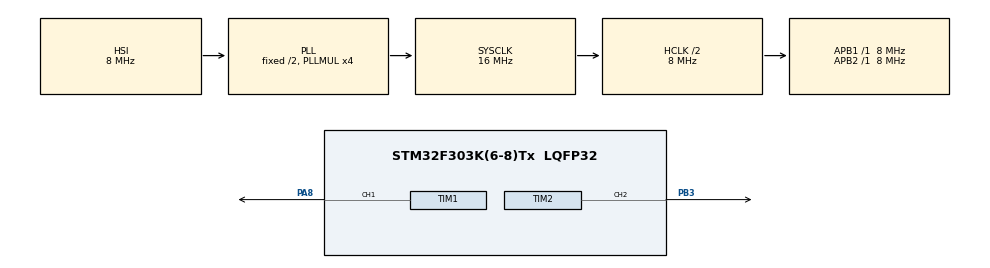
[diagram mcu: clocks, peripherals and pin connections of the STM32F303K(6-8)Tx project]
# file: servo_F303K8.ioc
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Mcu.Family=STM32F3
Mcu.Name=STM32F303K(6-8)Tx
Mcu.Package=LQFP32
NVIC.PriorityGroup=NVIC_PRIORITYGROUP_4
PA8.Signal=S_TIM1_CH1
PB3.Signal=S_TIM2_CH2
ProjectManager.HeapSize=0x200
ProjectManager.StackSize=0x400
ProjectManager.TargetToolchain=STM32CubeIDE
RCC.AHBCLKDivider=RCC_SYSCLK_DIV2
RCC.AHBFreq_Value=8000000
RCC.APB1Freq_Value=8000000
RCC.APB1TimFreq_Value=8000000
RCC.APB2Freq_Value=8000000
RCC.APB2TimFreq_Value=8000000
RCC.CortexFreq_Value=8000000
RCC.HCLKFreq_Value=8000000
RCC.HSE_VALUE=8000000
RCC.HSI_VALUE=8000000
RCC.PLLMUL=RCC_PLL_MUL4
RCC.SYSCLKFreq_VALUE=16000000
RCC.SYSCLKSourceVirtual=RCC_SYSCLKSOURCE_PLLCLK
SH.S_TIM1_CH1.0=TIM1_CH1,PWM Generation1 CH1
SH.S_TIM2_CH2.0=TIM2_CH2,PWM Generation2 CH2
TIM1.Channel-PWM\ Generation1\ CH1=TIM_CHANNEL_1
TIM1.Period=255
TIM1.Prescaler=624
TIM2.Channel-PWM\ Generation2\ CH2=TIM_CHANNEL_2
TIM2.Period=255
TIM2.Prescaler=625
VP_TIM1_VS_ClockSourceINT.Mode=Internal
VP_TIM2_VS_ClockSourceINT.Mode=Internal
board=custom

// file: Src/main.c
/* USER CODE BEGIN Header */
/**
  ******************************************************************************
  * @file           : main.c
  * @brief          : Main program body
  ******************************************************************************
  * @attention
  *
  * <h2><center>&copy; Copyright (c) 2020 STMicroelectronics.
  * All rights reserved.</center></h2>
  *
  * This software component is licensed by ST under BSD 3-Clause license,
  * the "License"; You may not use this file except in compliance with the
  * License. You may obtain a copy of the License at:
  *                        opensource.org/licenses/BSD-3-Clause
  *
  ******************************************************************************
  */
/* USER CODE END Header */

#include "main.h"

TIM_HandleTypeDef htim1;
TIM_HandleTypeDef htim2;

void SystemClock_Config(void);
static void MX_GPIO_Init(void);
static void MX_TIM1_Init(void);
static void MX_TIM2_Init(void);

int main(void)
{

  /* MCU Configuration--------------------------------------------------------*/

  /* Reset of all peripherals, Initializes the Flash interface and the Systick. */
  HAL_Init();

  /* Configure the system clock */
  SystemClock_Config();

  /* Initialize all configured peripherals */
  MX_GPIO_Init();
  MX_TIM1_Init();
  MX_TIM2_Init();
  /* USER CODE BEGIN 2 */
  char txbuf[30]={0};
   uint16_t value=0;
   short duty;

   HAL_TIM_PWM_Start(&htim1,TIM_CHANNEL_1);
   HAL_TIM_PWM_Start(&htim2,TIM_CHANNEL_2);

  /* USER CODE END 2 */

  /* Infinite loop */
  while (1)
  {

    /* USER CODE BEGIN 3 */

	  duty=8;
	 __HAL_TIM_SET_COMPARE(&htim1,TIM_CHANNEL_1,duty);
	 __HAL_TIM_SET_COMPARE(&htim2,TIM_CHANNEL_2,0);
	 HAL_Delay(1000);
     duty=32;
      __HAL_TIM_SET_COMPARE(&htim1,TIM_CHANNEL_1,duty);
      __HAL_TIM_SET_COMPARE(&htim2,TIM_CHANNEL_2,50);
      HAL_Delay(1000);

  }
  /* USER CODE END 3 */
}

void SystemClock_Config(void)
{
  RCC_OscInitTypeDef RCC_OscInitStruct = {0};
  RCC_ClkInitTypeDef RCC_ClkInitStruct = {0};
  RCC_PeriphCLKInitTypeDef PeriphClkInit = {0};

  /** Initializes the CPU, AHB and APB busses clocks
  */
  RCC_OscInitStruct.OscillatorType = RCC_OSCILLATORTYPE_HSI;
  RCC_OscInitStruct.HSIState = RCC_HSI_ON;
  RCC_OscInitStruct.HSICalibrationValue = RCC_HSICALIBRATION_DEFAULT;
  RCC_OscInitStruct.PLL.PLLState = RCC_PLL_ON;
  RCC_OscInitStruct.PLL.PLLSource = RCC_PLLSOURCE_HSI;
  RCC_OscInitStruct.PLL.PLLMUL = RCC_PLL_MUL4;
  if (HAL_RCC_OscConfig(&RCC_OscInitStruct) != HAL_OK)
  {
    Error_Handler();
  }
  /** Initializes the CPU, AHB and APB busses clocks
  */
  RCC_ClkInitStruct.ClockType = RCC_CLOCKTYPE_HCLK|RCC_CLOCKTYPE_SYSCLK
                              |RCC_CLOCKTYPE_PCLK1|RCC_CLOCKTYPE_PCLK2;
  RCC_ClkInitStruct.SYSCLKSource = RCC_SYSCLKSOURCE_PLLCLK;
  RCC_ClkInitStruct.AHBCLKDivider = RCC_SYSCLK_DIV2;
  RCC_ClkInitStruct.APB1CLKDivider = RCC_HCLK_DIV1;
  RCC_ClkInitStruct.APB2CLKDivider = RCC_HCLK_DIV1;

  if (HAL_RCC_ClockConfig(&RCC_ClkInitStruct, FLASH_LATENCY_0) != HAL_OK)
  {
    Error_Handler();
  }
  PeriphClkInit.PeriphClockSelection = RCC_PERIPHCLK_TIM1;
  PeriphClkInit.Tim1ClockSelection = RCC_TIM1CLK_HCLK;
  if (HAL_RCCEx_PeriphCLKConfig(&PeriphClkInit) != HAL_OK)
  {
    Error_Handler();
  }
}

static void MX_TIM1_Init(void)
{

  TIM_ClockConfigTypeDef sClockSourceConfig = {0};
  TIM_MasterConfigTypeDef sMasterConfig = {0};
  TIM_OC_InitTypeDef sConfigOC = {0};
  TIM_BreakDeadTimeConfigTypeDef sBreakDeadTimeConfig = {0};

  htim1.Instance = TIM1;
  htim1.Init.Prescaler = 624;
  htim1.Init.CounterMode = TIM_COUNTERMODE_UP;
  htim1.Init.Period = 255;
  htim1.Init.ClockDivision = TIM_CLOCKDIVISION_DIV1;
  htim1.Init.RepetitionCounter = 0;
  htim1.Init.AutoReloadPreload = TIM_AUTORELOAD_PRELOAD_DISABLE;
  if (HAL_TIM_Base_Init(&htim1) != HAL_OK)
  {
    Error_Handler();
  }
  sClockSourceConfig.ClockSource = TIM_CLOCKSOURCE_INTERNAL;
  if (HAL_TIM_ConfigClockSource(&htim1, &sClockSourceConfig) != HAL_OK)
  {
    Error_Handler();
  }
  if (HAL_TIM_PWM_Init(&htim1) != HAL_OK)
  {
    Error_Handler();
  }
  sMasterConfig.MasterOutputTrigger = TIM_TRGO_RESET;
  sMasterConfig.MasterOutputTrigger2 = TIM_TRGO2_RESET;
  sMasterConfig.MasterSlaveMode = TIM_MASTERSLAVEMODE_DISABLE;
  if (HAL_TIMEx_MasterConfigSynchronization(&htim1, &sMasterConfig) != HAL_OK)
  {
    Error_Handler();
  }
  sConfigOC.OCMode = TIM_OCMODE_PWM1;
  sConfigOC.Pulse = 0;
  sConfigOC.OCPolarity = TIM_OCPOLARITY_HIGH;
  sConfigOC.OCNPolarity = TIM_OCNPOLARITY_HIGH;
  sConfigOC.OCFastMode = TIM_OCFAST_DISABLE;
  sConfigOC.OCIdleState = TIM_OCIDLESTATE_RESET;
  sConfigOC.OCNIdleState = TIM_OCNIDLESTATE_RESET;
  if (HAL_TIM_PWM_ConfigChannel(&htim1, &sConfigOC, TIM_CHANNEL_1) != HAL_OK)
  {
    Error_Handler();
  }
  sBreakDeadTimeConfig.OffStateRunMode = TIM_OSSR_DISABLE;
  sBreakDeadTimeConfig.OffStateIDLEMode = TIM_OSSI_DISABLE;
  sBreakDeadTimeConfig.LockLevel = TIM_LOCKLEVEL_OFF;
  sBreakDeadTimeConfig.DeadTime = 0;
  sBreakDeadTimeConfig.BreakState = TIM_BREAK_DISABLE;
  sBreakDeadTimeConfig.BreakPolarity = TIM_BREAKPOLARITY_HIGH;
  sBreakDeadTimeConfig.BreakFilter = 0;
  sBreakDeadTimeConfig.Break2State = TIM_BREAK2_DISABLE;
  sBreakDeadTimeConfig.Break2Polarity = TIM_BREAK2POLARITY_HIGH;
  sBreakDeadTimeConfig.Break2Filter = 0;
  sBreakDeadTimeConfig.AutomaticOutput = TIM_AUTOMATICOUTPUT_DISABLE;
  if (HAL_TIMEx_ConfigBreakDeadTime(&htim1, &sBreakDeadTimeConfig) != HAL_OK)
  {
    Error_Handler();
  }
  HAL_TIM_MspPostInit(&htim1);

}

static void MX_TIM2_Init(void)
{

  TIM_ClockConfigTypeDef sClockSourceConfig = {0};
  TIM_MasterConfigTypeDef sMasterConfig = {0};
  TIM_OC_InitTypeDef sConfigOC = {0};

  htim2.Instance = TIM2;
  htim2.Init.Prescaler = 625;
  htim2.Init.CounterMode = TIM_COUNTERMODE_UP;
  htim2.Init.Period = 255;
  htim2.Init.ClockDivision = TIM_CLOCKDIVISION_DIV1;
  htim2.Init.AutoReloadPreload = TIM_AUTORELOAD_PRELOAD_DISABLE;
  if (HAL_TIM_Base_Init(&htim2) != HAL_OK)
  {
    Error_Handler();
  }
  sClockSourceConfig.ClockSource = TIM_CLOCKSOURCE_INTERNAL;
  if (HAL_TIM_ConfigClockSource(&htim2, &sClockSourceConfig) != HAL_OK)
  {
    Error_Handler();
  }
  if (HAL_TIM_PWM_Init(&htim2) != HAL_OK)
  {
    Error_Handler();
  }
  sMasterConfig.MasterOutputTrigger = TIM_TRGO_RESET;
  sMasterConfig.MasterSlaveMode = TIM_MASTERSLAVEMODE_DISABLE;
  if (HAL_TIMEx_MasterConfigSynchronization(&htim2, &sMasterConfig) != HAL_OK)
  {
    Error_Handler();
  }
  sConfigOC.OCMode = TIM_OCMODE_PWM1;
  sConfigOC.Pulse = 0;
  sConfigOC.OCPolarity = TIM_OCPOLARITY_HIGH;
  sConfigOC.OCFastMode = TIM_OCFAST_DISABLE;
  if (HAL_TIM_PWM_ConfigChannel(&htim2, &sConfigOC, TIM_CHANNEL_2) != HAL_OK)
  {
    Error_Handler();
  }
  HAL_TIM_MspPostInit(&htim2);

}

static void MX_GPIO_Init(void)
{

  /* GPIO Ports Clock Enable */
  __HAL_RCC_GPIOA_CLK_ENABLE();
  __HAL_RCC_GPIOB_CLK_ENABLE();

}

void Error_Handler(void)
{
}

/************************ (C) COPYRIGHT STMicroelectronics *****END OF FILE****/
